# STM32N657xx register map
File version: 1.0
Registers are 32-bit, read-write, reset 0x0 unless marked. A register's access mark holds for its fields unless they carry their own. Offsets are from the block's base; [hi:lo] are bit positions; {n}, {i} and the like mark numbered series.

## RCC (part 2 of 2) — Reset and Clock Control
Base 0x46028000
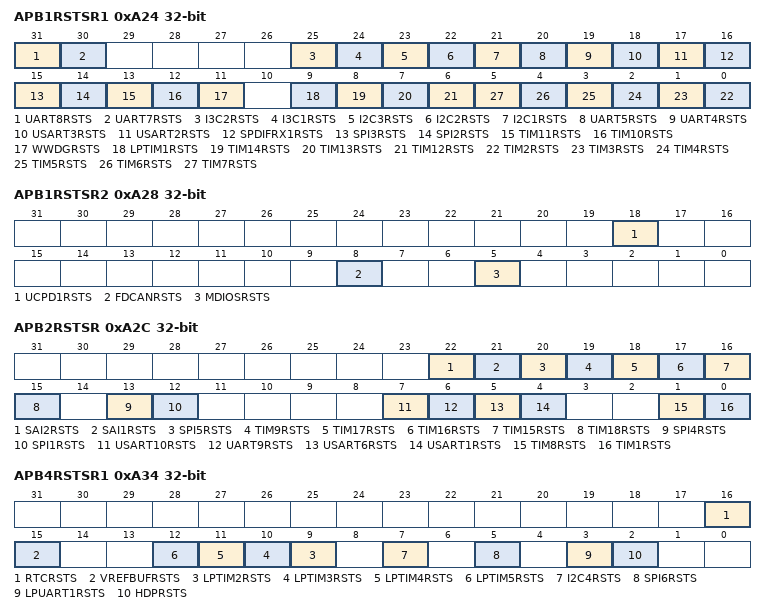
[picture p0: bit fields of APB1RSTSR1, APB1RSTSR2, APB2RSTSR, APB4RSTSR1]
0xA24 APB1RSTSR1 — RCC APB1 reset register 1
  [31] UART8RSTS — UART8 reset
  [30] UART7RSTS — UART7 reset
  [25] I3C2RSTS — I3C2 reset
  [24] I3C1RSTS — I3C1 reset
  [23] I2C3RSTS — I2C3 reset
  [22] I2C2RSTS — I2C2 reset
  [21] I2C1RSTS — I2C1 reset
  [20] UART5RSTS — UART5 reset
  [19] UART4RSTS — UART4 reset
  [18] USART3RSTS — USART3 reset
  [17] USART2RSTS — USART2 reset
  [16] SPDIFRX1RSTS — SPDIFRX1 reset
  [15] SPI3RSTS — SPI3 reset
  [14] SPI2RSTS — SPI2 reset
  [13] TIM11RSTS — TIM11 reset
  [12] TIM10RSTS — TIM10 reset
  [11] WWDGRSTS — WWDG reset
  [9] LPTIM1RSTS — LPTIM1 reset
  [8] TIM14RSTS — TIM14 reset
  [7] TIM13RSTS — TIM13 reset
  [6] TIM12RSTS — TIM12 reset
  [n-2] TIM{n}RSTS (n=2..7) — TIM{n} reset
0xA28 APB1RSTSR2 — RCC APB1 reset register 2
  [18] UCPD1RSTS — UCPD1 reset
  [8] FDCANRSTS — FDCAN reset
  [5] MDIOSRSTS — MDIOS reset
0xA2C APB2RSTSR — RCC APB2 reset register
  [22] SAI2RSTS — SAI2 reset
  [21] SAI1RSTS — SAI1 reset
  [20] SPI5RSTS — SPI5 reset
  [19] TIM9RSTS — TIM9 reset
  [18] TIM17RSTS — TIM17 reset
  [17] TIM16RSTS — TIM16 reset
  [16] TIM15RSTS — TIM15 reset
  [15] TIM18RSTS — TIM18 reset
  [13] SPI4RSTS — SPI4 reset
  [12] SPI1RSTS — SPI1 reset
  [7] USART10RSTS — USART10 reset
  [6] UART9RSTS — UART9 reset
  [5] USART6RSTS — USART6 reset
  [4] USART1RSTS — USART1 reset
  [1] TIM8RSTS — TIM8 reset
  [0] TIM1RSTS — TIM1 reset
0xA34 APB4RSTSR1 — RCC APB4 reset register 1
  [16] RTCRSTS — RTC reset
  [15] VREFBUFRSTS — VREFBUF reset
  [n+7] LPTIM{n}RSTS (n=2..5) — LPTIM{n} reset
  [7] I2C4RSTS — I2C4 reset
  [5] SPI6RSTS — SPI6 reset
  [3] LPUART1RSTS — LPUART1 reset
  [2] HDPRSTS — HDP reset
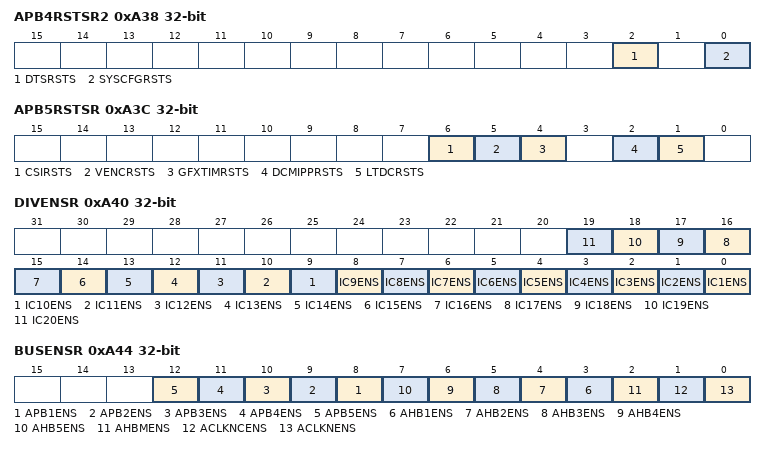
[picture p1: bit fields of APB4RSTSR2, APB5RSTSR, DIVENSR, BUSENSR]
0xA38 APB4RSTSR2 — RCC APB4 reset register 2
  [2] DTSRSTS — DTS reset
  [0] SYSCFGRSTS — SYSCFG reset
0xA3C APB5RSTSR — RCC APB5 reset register
  [6] CSIRSTS — CSI reset
  [5] VENCRSTS — VENC reset
  [4] GFXTIMRSTS — GFXTIM reset
  [2] DCMIPPRSTS — DCMIPP reset
  [1] LTDCRSTS — LTDC reset
0xA40 DIVENSR — RCC divider enable register
  [n-1] IC{n}ENS (n=1..20) — IC{n} enable
0xA44 BUSENSR — RCC bus enable register
  [n+7] APB{n}ENS (n=1..5) — APB{n} enable
  [n+2] AHB{n}ENS (n=1..5) — AHB{n} enable
  [2] AHBMENS — AHBM enable
  [1] ACLKNCENS — ACLKNC enable
  [0] ACLKNENS — ACLKN enable
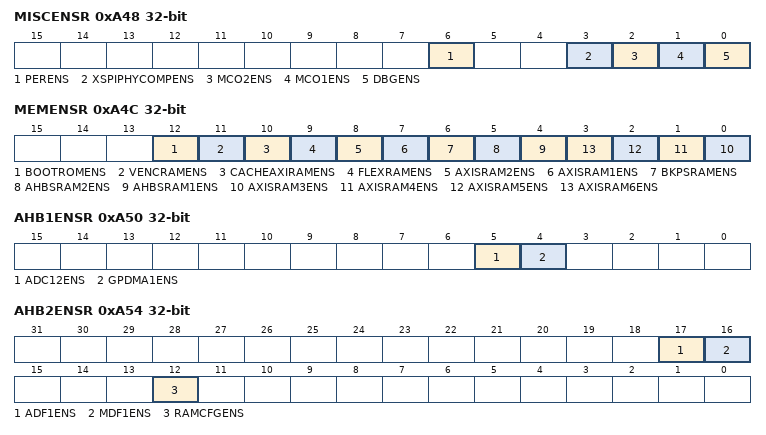
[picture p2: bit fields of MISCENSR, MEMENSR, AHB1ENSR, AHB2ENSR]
0xA48 MISCENSR — RCC miscellaneous enable register
  [6] PERENS — PER enable
  [3] XSPIPHYCOMPENS — XSPIPHYCOMP enable
  [2] MCO2ENS — MCO2 enable
  [1] MCO1ENS — MCO1 enable
  [0] DBGENS — DBG enable
0xA4C MEMENSR — RCC memory enable register
  [12] BOOTROMENS — Boot ROM enable
  [11] VENCRAMENS — VENCRAM enable
  [10] CACHEAXIRAMENS — CACHEAXIRAM enable
  [9] FLEXRAMENS — FLEXRAM enable
  [8] AXISRAM2ENS — AXISRAM2 enable
  [7] AXISRAM1ENS — AXISRAM1 enable
  [6] BKPSRAMENS — BKPSRAM enable
  [5] AHBSRAM2ENS — AHBSRAM2 enable
  [4] AHBSRAM1ENS — AHBSRAM1 enable
  [n-3] AXISRAM{n}ENS (n=3..6) — AXISRAM{n} enable
0xA50 AHB1ENSR — RCC AHB1 enable register
  [5] ADC12ENS — ADC12 enable
  [4] GPDMA1ENS — GPDMA1 enable
0xA54 AHB2ENSR — RCC AHB2 enable register
  [17] ADF1ENS — ADF1 enable
  [16] MDF1ENS — MDF1 enable
  [12] RAMCFGENS — RAMCFG enable
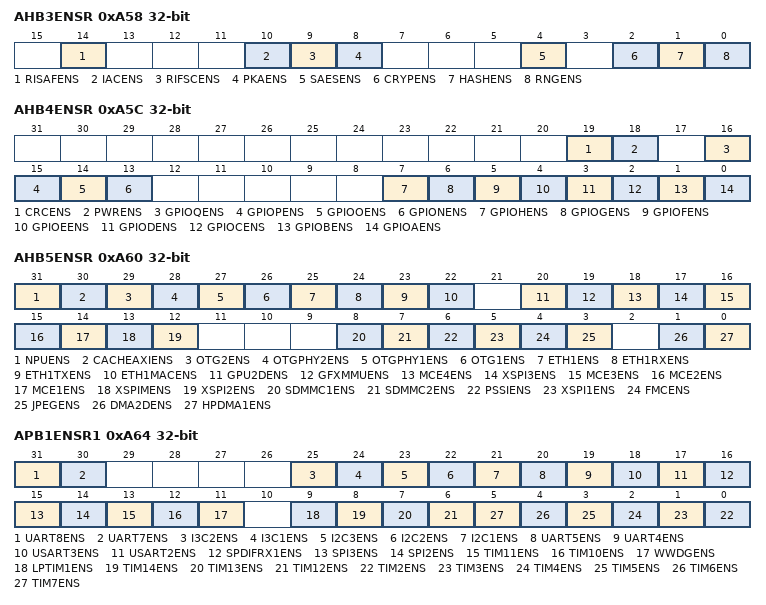
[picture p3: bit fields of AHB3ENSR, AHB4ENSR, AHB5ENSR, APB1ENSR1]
0xA58 AHB3ENSR — RCC AHB3 enable register
  [14] RISAFENS — RISAF enable
  [10] IACENS — IAC enable
  [9] RIFSCENS — RIFSC enable
  [8] PKAENS — PKA enable
  [4] SAESENS — SAES enable
  [2] CRYPENS — CRYP enable
  [1] HASHENS — HASH enable
  [0] RNGENS — RNG enable
0xA5C AHB4ENSR — RCC AHB4 enable register
  [19] CRCENS — CRC enable
  [18] PWRENS — PWR enable
  [16] GPIOQENS — GPIO Q enable
  [15] GPIOPENS — GPIO P enable
  [14] GPIOOENS — GPIO O enable
  [13] GPIONENS — GPIO N enable
  [7] GPIOHENS — GPIO H enable
  [6] GPIOGENS — GPIO G enable
  [5] GPIOFENS — GPIO F enable
  [4] GPIOEENS — GPIO E enable
  [3] GPIODENS — GPIO D enable
  [2] GPIOCENS — GPIO C enable
  [1] GPIOBENS — GPIO B enable
  [0] GPIOAENS — GPIO A enable
0xA60 AHB5ENSR — RCC AHB5 enable register
  [31] NPUENS — NPU enable
  [30] CACHEAXIENS — CACHEAXI enable
  [29] OTG2ENS — OTG2 enable
  [28] OTGPHY2ENS — OTGPHY2 enable
  [27] OTGPHY1ENS — OTGPHY1 enable
  [26] OTG1ENS — OTG1 enable
  [25] ETH1ENS — ETH1 enable
  [24] ETH1RXENS — ETH1RX enable
  [23] ETH1TXENS — ETH1TX enable
  [22] ETH1MACENS — ETH1MAC enable
  [20] GPU2DENS — GPU2D enable
  [19] GFXMMUENS — GFXMMU enable
  [18] MCE4ENS — MCE4 enable
  [17] XSPI3ENS — XSPI3 enable
  [16] MCE3ENS — MCE3 enable
  [15] MCE2ENS — MCE2 enable
  [14] MCE1ENS — MCE1 enable
  [13] XSPIMENS — XSPIM enable
  [12] XSPI2ENS — XSPI2 enable
  [8] SDMMC1ENS — SDMMC1 enable
  [7] SDMMC2ENS — SDMMC2 enable
  [6] PSSIENS — PSSI enable
  [5] XSPI1ENS — XSPI1 enable
  [4] FMCENS — FMC enable
  [3] JPEGENS — JPEG enable
  [1] DMA2DENS — DMA2D enable
  [0] HPDMA1ENS — HPDMA1 enable
0xA64 APB1ENSR1 — RCC APB1 enable register 1
  [31] UART8ENS — UART8 enable
  [30] UART7ENS — UART7 enable
  [25] I3C2ENS — I3C2 enable
  [24] I3C1ENS — I3C1 enable
  [23] I2C3ENS — I2C3 enable
  [22] I2C2ENS — I2C2 enable
  [21] I2C1ENS — I2C1 enable
  [20] UART5ENS — UART5 enable
  [19] UART4ENS — UART4 enable
  [18] USART3ENS — USART3 enable
  [17] USART2ENS — USART2 enable
  [16] SPDIFRX1ENS — SPDIFRX1 enable
  [15] SPI3ENS — SPI3 enable
  [14] SPI2ENS — SPI2 enable
  [13] TIM11ENS — TIM11 enable
  [12] TIM10ENS — TIM10 enable
  [11] WWDGENS — WWDG enable
  [9] LPTIM1ENS — LPTIM1 enable
  [8] TIM14ENS — TIM14 enable
  [7] TIM13ENS — TIM13 enable
  [6] TIM12ENS — TIM12 enable
  [n-2] TIM{n}ENS (n=2..7) — TIM{n} enable
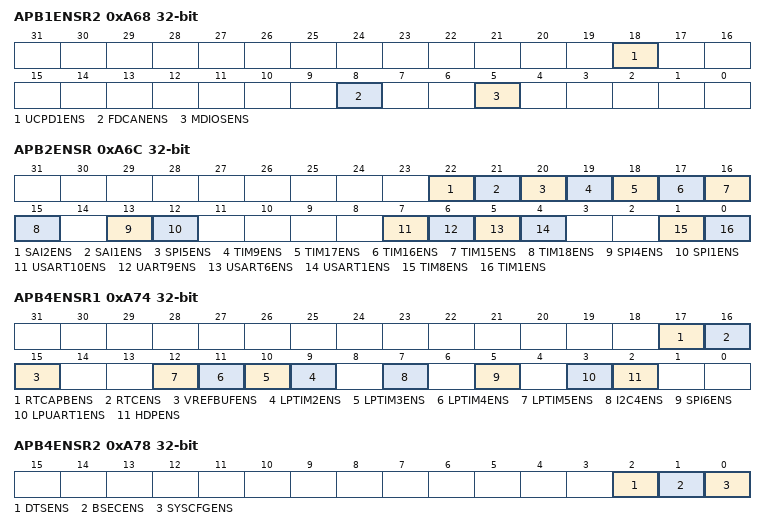
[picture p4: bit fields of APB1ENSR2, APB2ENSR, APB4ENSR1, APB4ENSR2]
0xA68 APB1ENSR2 — RCC APB1 enable register 2
  [18] UCPD1ENS — UCPD1 enable
  [8] FDCANENS — FDCAN enable
  [5] MDIOSENS — MDIOS enable
0xA6C APB2ENSR — RCC APB2 enable register
  [22] SAI2ENS — SAI2 enable
  [21] SAI1ENS — SAI1 enable
  [20] SPI5ENS — SPI5 enable
  [19] TIM9ENS — TIM9 enable
  [18] TIM17ENS — TIM17 enable
  [17] TIM16ENS — TIM16 enable
  [16] TIM15ENS — TIM15 enable
  [15] TIM18ENS — TIM18 enable
  [13] SPI4ENS — SPI4 enable
  [12] SPI1ENS — SPI1 enable
  [7] USART10ENS — USART10 enable
  [6] UART9ENS — UART9 enable
  [5] USART6ENS — USART6 enable
  [4] USART1ENS — USART1 enable
  [1] TIM8ENS — TIM8 enable
  [0] TIM1ENS — TIM1 enable
0xA70 APB3ENSR — RCC APB3 enable register
  [2] DFTENS — DFT enable
0xA74 APB4ENSR1 — RCC APB4 enable register 1
  [17] RTCAPBENS — RTCAPB enable
  [16] RTCENS — RTC enable
  [15] VREFBUFENS — VREFBUF enable
  [n+7] LPTIM{n}ENS (n=2..5) — LPTIM{n} enable
  [7] I2C4ENS — I2C4 enable
  [5] SPI6ENS — SPI6 enable
  [3] LPUART1ENS — LPUART1 enable
  [2] HDPENS — HDP enable
0xA78 APB4ENSR2 — RCC APB4 enable register 2
  [2] DTSENS — DTS enable
  [1] BSECENS — BSEC enable
  [0] SYSCFGENS — SYSCFG enable
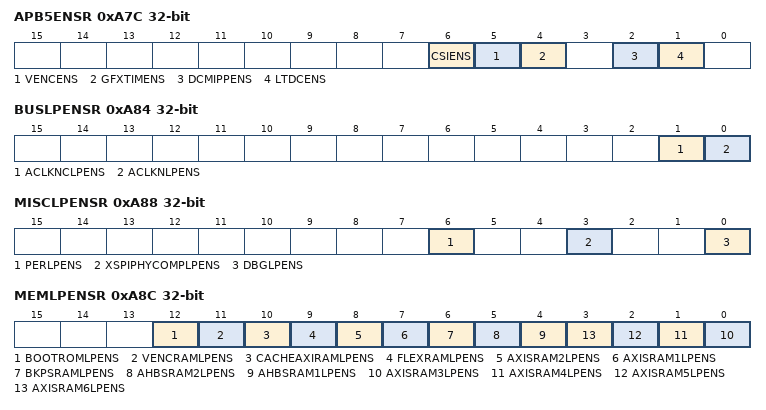
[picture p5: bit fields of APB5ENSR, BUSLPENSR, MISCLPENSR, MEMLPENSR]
0xA7C APB5ENSR — RCC APB5 enable register
  [6] CSIENS — CSI enable
  [5] VENCENS — VENC enable
  [4] GFXTIMENS — GFXTIM enable
  [2] DCMIPPENS — DCMIPP enable
  [1] LTDCENS — LTDC enable
0xA84 BUSLPENSR — RCC bus sleep enable register
  [1] ACLKNCLPENS — ACLKNC enable
  [0] ACLKNLPENS — ACLKN enable
0xA88 MISCLPENSR — RCC miscellaneous sleep enable register
  [6] PERLPENS — PER enable
  [3] XSPIPHYCOMPLPENS — XSPIPHYCOMP enable
  [0] DBGLPENS — DBG enable
0xA8C MEMLPENSR — RCC memory sleep enable register
  [12] BOOTROMLPENS — Boot ROM enable
  [11] VENCRAMLPENS — VENCRAM enable
  [10] CACHEAXIRAMLPENS — CACHEAXIRAM enable
  [9] FLEXRAMLPENS — FLEXRAM enable
  [8] AXISRAM2LPENS — AXISRAM2 enable
  [7] AXISRAM1LPENS — AXISRAM1 enable
  [6] BKPSRAMLPENS — BKPSRAM enable
  [5] AHBSRAM2LPENS — AHBSRAM2 enable
  [4] AHBSRAM1LPENS — AHBSRAM1 enable
  [n-3] AXISRAM{n}LPENS (n=3..6) — AXISRAM{n} enable
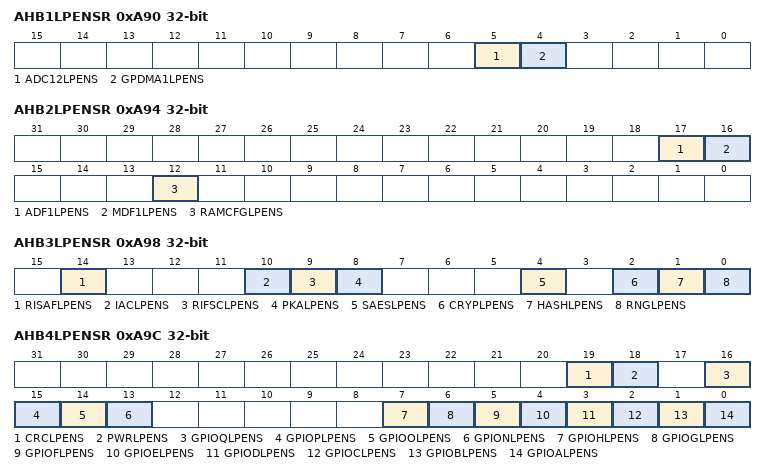
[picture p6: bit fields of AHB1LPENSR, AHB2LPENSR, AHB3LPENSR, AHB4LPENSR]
0xA90 AHB1LPENSR — RCC AHB1 sleep enable register
  [5] ADC12LPENS — ADC12 enable
  [4] GPDMA1LPENS — GPDMA1 enable
0xA94 AHB2LPENSR — RCC AHB2 sleep enable register
  [17] ADF1LPENS — ADF1 enable
  [16] MDF1LPENS — MDF1 enable
  [12] RAMCFGLPENS — RAMCFG enable
0xA98 AHB3LPENSR — RCC AHB3 sleep enable register
  [14] RISAFLPENS — RISAF enable
  [10] IACLPENS — IAC enable in Sleep mode
  [9] RIFSCLPENS — RIFSC enable
  [8] PKALPENS — PKA enable
  [4] SAESLPENS — SAES enable
  [2] CRYPLPENS — CRYP enable
  [1] HASHLPENS — HASH enable
  [0] RNGLPENS — RNG enable
0xA9C AHB4LPENSR — RCC AHB4 sleep enable register
  [19] CRCLPENS — CRC enable
  [18] PWRLPENS — PWR enable
  [16] GPIOQLPENS — GPIO Q enable
  [15] GPIOPLPENS — GPIO P enable
  [14] GPIOOLPENS — GPIO O enable
  [13] GPIONLPENS — GPIO N enable
  [7] GPIOHLPENS — GPIO H enable
  [6] GPIOGLPENS — GPIO G enable
  [5] GPIOFLPENS — GPIO F enable
  [4] GPIOELPENS — GPIO E enable
  [3] GPIODLPENS — GPIO D enable
  [2] GPIOCLPENS — GPIO C enable
  [1] GPIOBLPENS — GPIO B enable
  [0] GPIOALPENS — GPIO A enable
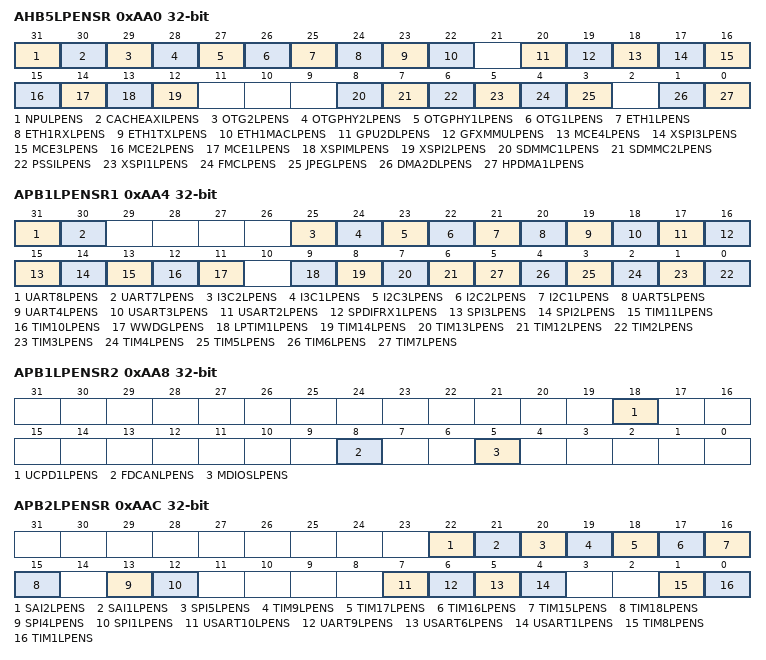
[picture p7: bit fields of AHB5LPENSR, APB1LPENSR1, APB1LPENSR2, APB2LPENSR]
0xAA0 AHB5LPENSR — RCC AHB5 sleep enable register
  [31] NPULPENS — NPU enable
  [30] CACHEAXILPENS — CACHEAXI enable
  [29] OTG2LPENS — OTG2 enable
  [28] OTGPHY2LPENS — OTGPHY2 enable
  [27] OTGPHY1LPENS — OTGPHY1 enable
  [26] OTG1LPENS — OTG1 enable
  [25] ETH1LPENS — ETH1 enable
  [24] ETH1RXLPENS — ETH1RX enable
  [23] ETH1TXLPENS — ETH1TX enable
  [22] ETH1MACLPENS — ETH1MAC enable
  [20] GPU2DLPENS — GPU2D enable
  [19] GFXMMULPENS — GFXMMU enable
  [18] MCE4LPENS — MCE4 enable
  [17] XSPI3LPENS — XSPI3 enable
  [16] MCE3LPENS — MCE3 enable
  [15] MCE2LPENS — MCE2 enable
  [14] MCE1LPENS — MCE1 enable
  [13] XSPIMLPENS — XSPIM enable
  [12] XSPI2LPENS — XSPI2 enable
  [8] SDMMC1LPENS — SDMMC1 enable
  [7] SDMMC2LPENS — SDMMC2 enable
  [6] PSSILPENS — PSSI enable
  [5] XSPI1LPENS — XSPI1 enable
  [4] FMCLPENS — FMC enable
  [3] JPEGLPENS — JPEG enable
  [1] DMA2DLPENS — DMA2D enable
  [0] HPDMA1LPENS — HPDMA1 enable
0xAA4 APB1LPENSR1 — RCC APB1 sleep enable register 1
  [31] UART8LPENS — UART8 enable
  [30] UART7LPENS — UART7 enable
  [25] I3C2LPENS — I3C2 enable
  [24] I3C1LPENS — I3C1 enable
  [23] I2C3LPENS — I2C3 enable
  [22] I2C2LPENS — I2C2 enable
  [21] I2C1LPENS — I2C1 enable
  [20] UART5LPENS — UART5 enable
  [19] UART4LPENS — UART4 enable
  [18] USART3LPENS — USART3 enable
  [17] USART2LPENS — USART2 enable
  [16] SPDIFRX1LPENS — SPDIFRX1 enable
  [15] SPI3LPENS — SPI3 enable
  [14] SPI2LPENS — SPI2 enable
  [13] TIM11LPENS — TIM11 enable
  [12] TIM10LPENS — TIM10 enable
  [11] WWDGLPENS — WWDG enable
  [9] LPTIM1LPENS — LPTIM1 enable
  [8] TIM14LPENS — TIM14 enable
  [7] TIM13LPENS — TIM13 enable
  [6] TIM12LPENS — TIM12 enable
  [n-2] TIM{n}LPENS (n=2..7) — TIM{n} enable
0xAA8 APB1LPENSR2 — RCC APB1 sleep enable register 2
  [18] UCPD1LPENS — UCPD1 enable
  [8] FDCANLPENS — FDCAN enable
  [5] MDIOSLPENS — MDIOS enable
0xAAC APB2LPENSR — RCC APB2 sleep enable register
  [22] SAI2LPENS — SAI2 enable
  [21] SAI1LPENS — SAI1 enable
  [20] SPI5LPENS — SPI5 enable
  [19] TIM9LPENS — TIM9 enable
  [18] TIM17LPENS — TIM17 enable
  [17] TIM16LPENS — TIM16 enable
  [16] TIM15LPENS — TIM15 enable
  [15] TIM18LPENS — TIM18 enable
  [13] SPI4LPENS — SPI4 enable
  [12] SPI1LPENS — SPI1 enable
  [7] USART10LPENS — USART10 enable
  [6] UART9LPENS — UART9 enable
  [5] USART6LPENS — USART6 enable
  [4] USART1LPENS — USART1 enable
  [1] TIM8LPENS — TIM8 enable
  [0] TIM1LPENS — TIM1 enable
0xAB0 APB3LPENSR — RCC APB3 sleep enable register
  [2] DFTLPENS — DFT enable
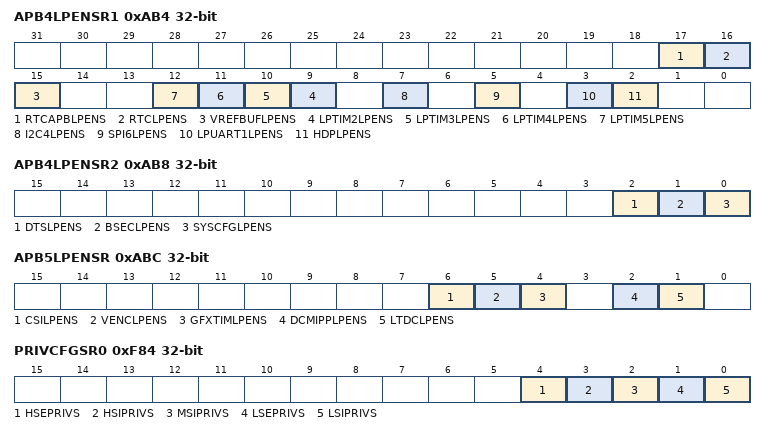
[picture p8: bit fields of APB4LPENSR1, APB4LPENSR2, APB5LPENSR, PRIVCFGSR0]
0xAB4 APB4LPENSR1 — RCC APB4 sleep enable register 1
  [17] RTCAPBLPENS — RTCAPB enable
  [16] RTCLPENS — RTC enable
  [15] VREFBUFLPENS — VREFBUF enable
  [n+7] LPTIM{n}LPENS (n=2..5) — LPTIM{n} enable
  [7] I2C4LPENS — I2C4 enable
  [5] SPI6LPENS — SPI6 enable
  [3] LPUART1LPENS — LPUART1 enable
  [2] HDPLPENS — HDP enable
0xAB8 APB4LPENSR2 — RCC APB4 sleep enable register 2
  [2] DTSLPENS — DTS enable
  [1] BSECLPENS — BSEC enable
  [0] SYSCFGLPENS — SYSCFG enable
0xABC APB5LPENSR — RCC APB5 sleep enable register
  [6] CSILPENS — CSI enable
  [5] VENCLPENS — VENC enable
  [4] GFXTIMLPENS — GFXTIM enable
  [2] DCMIPPLPENS — DCMIPP enable
  [1] LTDCLPENS — LTDC enable
0xF84 PRIVCFGSR0 — RCC oscillator privilege configuration set register 0
  [4] HSEPRIVS — Privileged protection of HSE configuration bits (enable, ready, divider)
  [3] HSIPRIVS — Privileged protection of HSI configuration bits (enable, ready, divider)
  [2] MSIPRIVS — Privileged protection of MSI configuration bits (enable, ready, divider)
  [1] LSEPRIVS — Privileged protection of LSE configuration bits (enable, ready, divider)
  [0] LSIPRIVS — Privileged protection of the LSI configuration bits (enable, ready, divider)
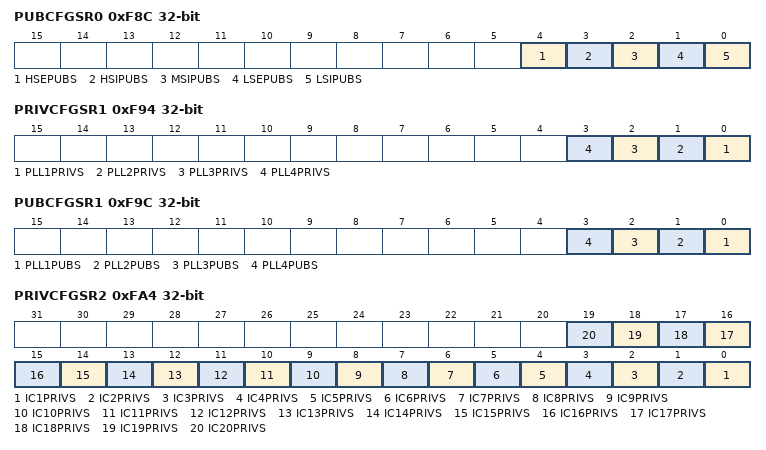
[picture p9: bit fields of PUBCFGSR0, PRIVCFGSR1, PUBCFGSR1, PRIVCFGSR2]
0xF8C PUBCFGSR0 — RCC oscillator public configuration set register 0
  [4] HSEPUBS — Public protection of he HSE configuration bits (enable, ready, divider)
  [3] HSIPUBS — Public protection of HSI configuration bits (enable, ready, divider)
  [2] MSIPUBS — Public protection of MSI configuration bits (enable, ready, divider)
  [1] LSEPUBS — Public protection of LSE configuration bits (enable, ready, divider)
  [0] LSIPUBS — Public protection of LSI configuration bits (enable, ready, divider)
0xF94 PRIVCFGSR1 — RCC PLL privilege configuration set register 1
  [n-1] PLL{n}PRIVS (n=1..4) — Privileged protection of PLL{n} configuration bits (enable, ready, divider)
0xF9C PUBCFGSR1 — RCC PLL public configuration set register 1
  [n-1] PLL{n}PUBS (n=1..4) — Public protection of PLL{n} configuration bits (enable, ready, divider)
0xFA4 PRIVCFGSR2 — RCC divider privilege configuration set register 2
  [n-1] IC{n}PRIVS (n=1..20) — Privileged protection of IC{n} configuration bits (enable, ready, divider)
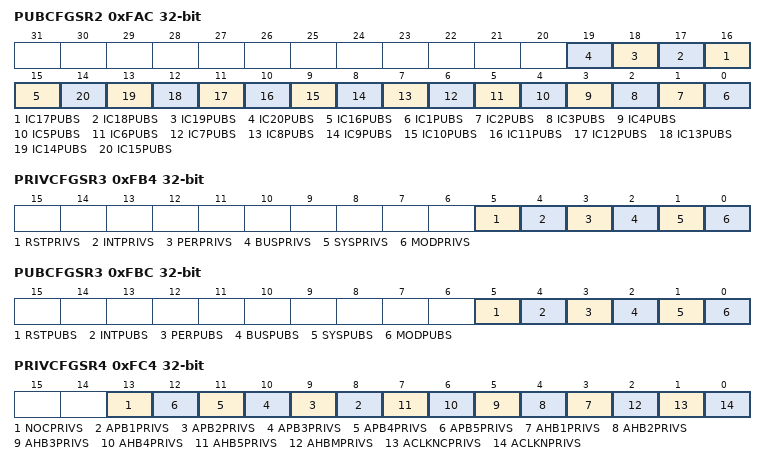
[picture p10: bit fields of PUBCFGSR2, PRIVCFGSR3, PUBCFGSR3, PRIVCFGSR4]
0xFAC PUBCFGSR2 — RCC divider public configuration set register 2
  [n-1] IC{n}PUBS (n=17..20) — Public protection of IC{n} configuration bits (enable, ready, divider)
  [15] IC16PUBS — Public protection of th IC16 configuration bits (enable, ready, divider
  [n-1] IC{n}PUBS (n=1..15) — Public protection of IC{n} configuration bits (enable, ready, divider)
0xFB4 PRIVCFGSR3 — RCC system privilege configuration set register 3
  [5] RSTPRIVS — Privileged protection of RST configuration bits (enable, ready, divider)
  [4] INTPRIVS — Privileged protection of INT configuration bits (enable, ready, divider)
  [3] PERPRIVS — Privileged protection of PER configuration bits (enable, ready, divider)
  [2] BUSPRIVS — Privileged protection of BUS configuration bits (enable, ready, divider)
  [1] SYSPRIVS — Privileged protection of SYS configuration bits (enable, ready, divider)
  [0] MODPRIVS — Privileged protection of MOD configuration bits (enable, ready, divider)
0xFBC PUBCFGSR3 — RCC system public configuration set register 3
  [5] RSTPUBS — Public protection of RST configuration bits (enable, ready, divider)
  [4] INTPUBS — Public protection of INT configuration bits (enable, ready, divider)
  [3] PERPUBS — Public protection of PER configuration bits (enable, ready, divider)
  [2] BUSPUBS — Public protection of BUS configuration bits (enable, ready, divider)
  [1] SYSPUBS — Public protection of SYS configuration bits (enable, ready, divider)
  [0] MODPUBS — Public protection of MOD configuration bits (enable, ready, divider)
0xFC4 PRIVCFGSR4 — RCC privilege configuration set register 4
  [13] NOCPRIVS — Privileged protection of NOC configuration bits (enable, ready, divider)
  [n+7] APB{n}PRIVS (n=1..5) — Privileged protection of APB{n} configuration bits (enable, ready, divider)
  [n+2] AHB{n}PRIVS (n=1..5) — Privileged protection of AHB{n} configuration bits (enable, ready, divider)
  [2] AHBMPRIVS — Privileged protection of AHBM configuration bits (enable, ready, divider)
  [1] ACLKNCPRIVS — Privileged protection of th ACLKNC configuration bits (enable, ready, divider)
  [0] ACLKNPRIVS — Privileged protection of ACLKN configuration bits (enable, ready, divider)
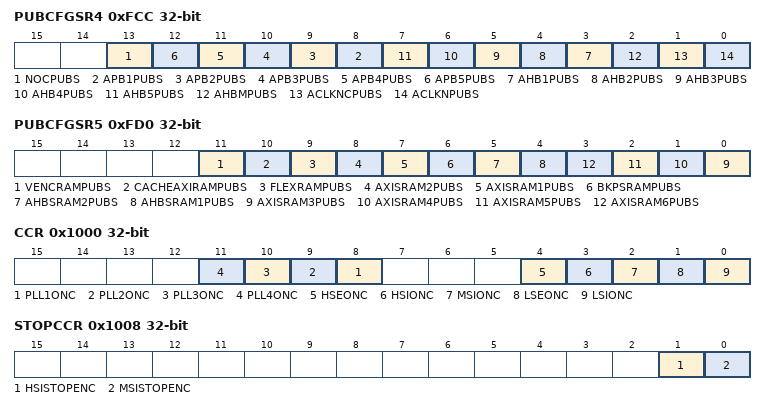
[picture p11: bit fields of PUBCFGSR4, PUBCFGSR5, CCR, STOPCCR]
0xFCC PUBCFGSR4 — RCC public configuration set register 4
  [13] NOCPUBS — Public protection of NOC configuration bits (enable, ready, divider)
  [n+7] APB{n}PUBS (n=1..5) — Public protection of APB{n} configuration bits (enable, ready, divider)
  [n+2] AHB{n}PUBS (n=1..5) — Public protection of AHB{n} configuration bits (enable, ready, divider)
  [2] AHBMPUBS — Public protection of AHBM configuration bits (enable, ready, divider)
  [1] ACLKNCPUBS — Public protection of ACLKNC configuration bits (enable, ready, divider)
  [0] ACLKNPUBS — Public protection of ACLKN configuration bits (enable, ready, divider)
0xFD0 PUBCFGSR5 — RCC public configuration set register 5
  [11] VENCRAMPUBS — Public protection of VENCRAM configuration bits (enable, ready, divider)
  [10] CACHEAXIRAMPUBS — Public protection of CACHEAXIRAM configuration bits (enable, ready, divider)
  [9] FLEXRAMPUBS — Public protection of FLEXRAM configuration bits (enable, ready, divider)
  [8] AXISRAM2PUBS — Public protection of AXISRAM2 configuration bits (enable, ready, divider)
  [7] AXISRAM1PUBS — Public protection of AXISRAM1 configuration bits (enable, ready, divider)
  [6] BKPSRAMPUBS — Public protection of BKPSRAM configuration bits (enable, ready, divider)
  [5] AHBSRAM2PUBS — Public protection of AHBSRAM2 configuration bits (enable, ready, divider)
  [4] AHBSRAM1PUBS — Public protection of AHBSRAM1 configuration bits (enable, ready, divider)
  [n-3] AXISRAM{n}PUBS (n=3..6) — Public protection of AXISRAM{n} configuration bits (enable, ready, divider)
0x1000 CCR — RCC control clear register
  [n+7] PLL{n}ONC (n=1..4) — PLL{n} oscillator enable
  [4] HSEONC — HSE oscillator enable
  [3] HSIONC — HSI oscillator enable
  [2] MSIONC — MSI oscillator enable
  [1] LSEONC — LSE oscillator enable
  [0] LSIONC — LSI oscillator enable
0x1008 STOPCCR — RCC Stop mode configuration clear register
  [1] HSISTOPENC — HSI oscillator enable
  [0] MSISTOPENC — MSI oscillator enable
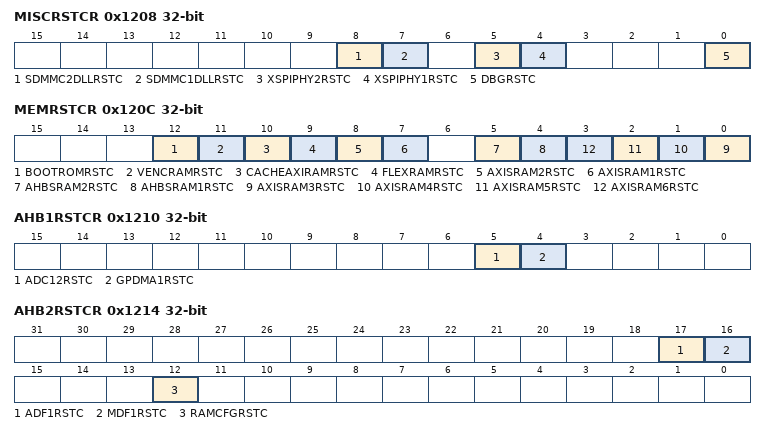
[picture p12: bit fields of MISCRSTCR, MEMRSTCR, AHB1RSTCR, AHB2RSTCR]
0x1208 MISCRSTCR — RCC miscellaneous reset clear register
  [8] SDMMC2DLLRSTC — SDMMC2DLL reset
  [7] SDMMC1DLLRSTC — SDMMC1DLL reset
  [5] XSPIPHY2RSTC — XSPIPHY2 reset
  [4] XSPIPHY1RSTC — XSPIPHY1 reset
  [0] DBGRSTC — DBG reset
0x120C MEMRSTCR — RCC memory reset clear register
  [12] BOOTROMRSTC — Boot ROM reset
  [11] VENCRAMRSTC — VENCRAM reset
  [10] CACHEAXIRAMRSTC — CACHEAXIRAM reset
  [9] FLEXRAMRSTC — FLEXRAM reset
  [8] AXISRAM2RSTC — AXISRAM2 reset
  [7] AXISRAM1RSTC — AXISRAM1 reset
  [5] AHBSRAM2RSTC — AHBSRAM2 reset
  [4] AHBSRAM1RSTC — AHBSRAM1 reset
  [n-3] AXISRAM{n}RSTC (n=3..6) — AXISRAM{n} reset
0x1210 AHB1RSTCR — RCC AHB1 reset clear register
  [5] ADC12RSTC — ADC12 reset
  [4] GPDMA1RSTC — GPDMA1 reset
0x1214 AHB2RSTCR — RCC AHB2 reset clear register
  [17] ADF1RSTC — ADF1 reset
  [16] MDF1RSTC — MDF1 reset
  [12] RAMCFGRSTC — RAMCFG reset
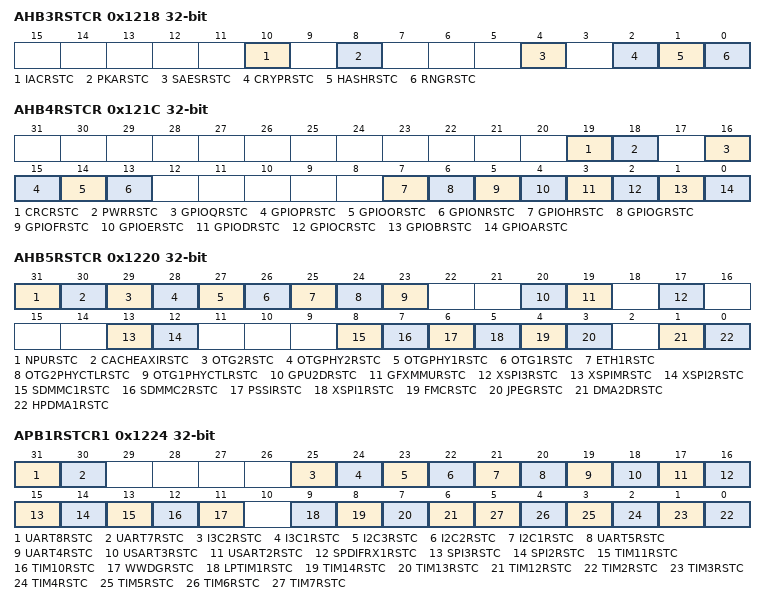
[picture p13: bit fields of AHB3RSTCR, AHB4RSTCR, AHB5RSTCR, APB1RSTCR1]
0x1218 AHB3RSTCR — RCC AHB3 reset r clear register
  [10] IACRSTC — IAC reset
  [8] PKARSTC — PKA reset
  [4] SAESRSTC — SAES reset
  [2] CRYPRSTC — CRYP reset
  [1] HASHRSTC — HASH reset
  [0] RNGRSTC — RNG reset
0x121C AHB4RSTCR — RCC AHB4 reset clear register
  [19] CRCRSTC — CRC reset
  [18] PWRRSTC — PWR reset
  [16] GPIOQRSTC — GPIO Q reset
  [15] GPIOPRSTC — GPIO P reset
  [14] GPIOORSTC — GPIO O reset
  [13] GPIONRSTC — GPIO N reset
  [7] GPIOHRSTC — GPIO H reset
  [6] GPIOGRSTC — GPIO G reset
  [5] GPIOFRSTC — GPIO F reset
  [4] GPIOERSTC — GPIO E reset
  [3] GPIODRSTC — GPIO D reset
  [2] GPIOCRSTC — GPIO C reset
  [1] GPIOBRSTC — GPIO B reset
  [0] GPIOARSTC — GPIO A reset
0x1220 AHB5RSTCR — RCC AHB5 reset clear register
  [31] NPURSTC — NPU reset
  [30] CACHEAXIRSTC — CACHEAXI reset
  [29] OTG2RSTC — OTG2 reset
  [28] OTGPHY2RSTC — OTGPHY2 reset
  [27] OTGPHY1RSTC — OTGPHY1 reset
  [26] OTG1RSTC — OTG1 reset
  [25] ETH1RSTC — ETH1 reset
  [24] OTG2PHYCTLRSTC — OTG2PHYCTL reset
  [23] OTG1PHYCTLRSTC — OTG1PHYCTL reset
  [20] GPU2DRSTC — GPU2D reset
  [19] GFXMMURSTC — GFXMMU reset
  [17] XSPI3RSTC — XSPI3 reset
  [13] XSPIMRSTC — XSPIM reset
  [12] XSPI2RSTC — XSPI2 reset
  [8] SDMMC1RSTC — SDMMC1 reset
  [7] SDMMC2RSTC — SDMMC2 reset
  [6] PSSIRSTC — PSSI reset
  [5] XSPI1RSTC — XSPI1 reset
  [4] FMCRSTC — FMC reset
  [3] JPEGRSTC — JPEG reset
  [1] DMA2DRSTC — DMA2D reset
  [0] HPDMA1RSTC — HPDMA1 reset
0x1224 APB1RSTCR1 — RCC APB1 reset clear register 1
  [31] UART8RSTC — UART8 reset
  [30] UART7RSTC — UART7 reset
  [25] I3C2RSTC — I3C2 reset
  [24] I3C1RSTC — I3C1 reset
  [23] I2C3RSTC — I2C3 reset
  [22] I2C2RSTC — I2C2 reset
  [21] I2C1RSTC — I2C1 reset
  [20] UART5RSTC — UART5 reset
  [19] UART4RSTC — UART4 reset
  [18] USART3RSTC — USART3 reset
  [17] USART2RSTC — USART2 reset
  [16] SPDIFRX1RSTC — SPDIFRX1 reset
  [15] SPI3RSTC — SPI3 reset
  [14] SPI2RSTC — SPI2 reset
  [13] TIM11RSTC — TIM11 reset
  [12] TIM10RSTC — TIM10 reset
  [11] WWDGRSTC — WWDG reset
  [9] LPTIM1RSTC — LPTIM1 reset
  [8] TIM14RSTC — TIM14 reset
  [7] TIM13RSTC — TIM13 reset
  [6] TIM12RSTC — TIM12 reset
  [n-2] TIM{n}RSTC (n=2..7) — TIM{n} reset
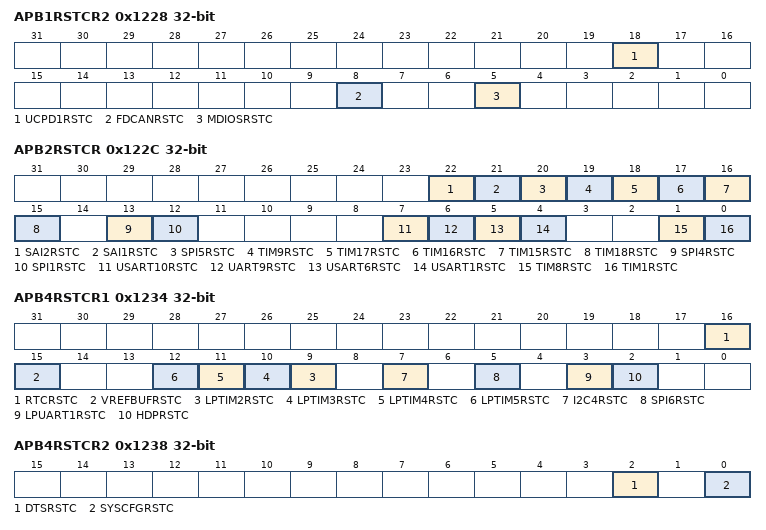
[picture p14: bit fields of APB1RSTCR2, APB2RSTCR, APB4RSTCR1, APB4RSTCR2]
0x1228 APB1RSTCR2 — RCC APB1 reset clear register 2
  [18] UCPD1RSTC — UCPD1 reset
  [8] FDCANRSTC — FDCAN reset
  [5] MDIOSRSTC — MDIOS reset
0x122C APB2RSTCR — RCC APB2 reset clear register
  [22] SAI2RSTC — SAI2 reset
  [21] SAI1RSTC — SAI1 reset
  [20] SPI5RSTC — SPI5 reset
  [19] TIM9RSTC — TIM9 reset
  [18] TIM17RSTC — TIM17 reset
  [17] TIM16RSTC — TIM16 reset
  [16] TIM15RSTC — TIM15 reset
  [15] TIM18RSTC — TIM18 reset
  [13] SPI4RSTC — SPI4 reset
  [12] SPI1RSTC — SPI1 reset
  [7] USART10RSTC — USART10 reset
  [6] UART9RSTC — UART9 reset
  [5] USART6RSTC — USART6 reset
  [4] USART1RSTC — USART1 reset
  [1] TIM8RSTC — TIM8 reset
  [0] TIM1RSTC — TIM1 reset
0x1234 APB4RSTCR1 — RCC APB4 reset clear register 1
  [16] RTCRSTC — RTC reset
  [15] VREFBUFRSTC — VREFBUF reset
  [n+7] LPTIM{n}RSTC (n=2..5) — LPTIM{n} reset
  [7] I2C4RSTC — I2C4 reset
  [5] SPI6RSTC — SPI6 reset
  [3] LPUART1RSTC — LPUART1 reset
  [2] HDPRSTC — HDP reset
0x1238 APB4RSTCR2 — RCC APB4 reset clear register 2
  [2] DTSRSTC — DTS reset
  [0] SYSCFGRSTC — SYSCFG reset
0x123C APB5RSTCR — RCC APB5 reset clear register
  [6] CSIRSTC — CSI reset
  [5] VENCRSTC — VENC reset
  [4] GFXTIMRSTC — GFXTIM reset
  [2] DCMIPPRSTC — DCMIPP reset
  [1] LTDCRSTC — LTDC reset
0x1240 DIVENCR — RCC divider enable clear register
  [n-1] IC{n}ENC (n=1..20) — IC{n} enable
0x1244 BUSENCR — RCC bus enable clear register
  [n+7] APB{n}ENC (n=1..5) — APB{n} enable
  [n+2] AHB{n}ENC (n=1..5) — AHB{n} enable
  [2] AHBMENC — AHBM enable
  [1] ACLKNCENC — ACLKNC enable
  [0] ACLKNENC — ACLKN enable
0x1248 MISCENCR — RCC miscellaneous enable clear register
  [6] PERENC — PER enable
  [3] XSPIPHYCOMPENC — XSPIPHYCOMP enable
  [2] MCO2ENC — MCO2 enable
  [1] MCO1ENC — MCO1 enable
  [0] DBGENC — DBG enable
0x124C MEMENCR — RCC memory enable clear register
  [12] BOOTROMENC — Boot ROM enable
  [11] VENCRAMENC — VENCRAM enable
  [10] CACHEAXIRAMENC — CACHEAXIRAM enable
  [9] FLEXRAMENC — FLEXRAM enable
  [8] AXISRAM2ENC — AXISRAM2 enable
  [7] AXISRAM1ENC — AXISRAM1 enable
  [6] BKPSRAMENC — BKPSRAM enable
  [5] AHBSRAM2ENC — AHBSRAM2 enable
  [4] AHBSRAM1ENC — AHBSRAM1 enable
  [n-3] AXISRAM{n}ENC (n=3..6) — AXISRAM{n} enable
0x1250 AHB1ENCR — RCC AHB1 enable clear register
  [5] ADC12ENC — ADC12 enable
  [4] GPDMA1ENC — GPDMA1 enable
0x1254 AHB2ENCR — RCC AHB2 enable clear register
  [17] ADF1ENC — ADF1 enable
  [16] MDF1ENC — MDF1 enable
  [12] RAMCFGENC — RAMCFG enable
0x1258 AHB3ENCR — RCC AHB3 enable clear register
  [14] RISAFENC — RISAF enable
  [10] IACENC — IAC enable
  [9] RIFSCENC — RIFSC enable
  [8] PKAENC — PKA enable
  [4] SAESENC — SAES enable
  [2] CRYPENC — CRYP enable
  [1] HASHENC — HASH enable
  [0] RNGENC — RNG enable
0x125C AHB4ENCR — RCC AHB4 enable clear register
  [19] CRCENC — CRC enable
  [18] PWRENC — PWR enable
  [16] GPIOQENC — GPIO Q enable
  [15] GPIOPENC — GPIO P enable
  [14] GPIOOENC — GPIO O enable
  [13] GPIONENC — GPIO N enable
  [7] GPIOHENC — GPIO H enable
  [6] GPIOGENC — GPIO G enable
  [5] GPIOFENC — GPIO F enable
  [4] GPIOEENC — GPIO E enable
  [3] GPIODENC — GPIO D enable
  [2] GPIOCENC — GPIO C enable
  [1] GPIOBENC — GPIO B enable
  [0] GPIOAENC — GPIO A enable
0x1260 AHB5ENCR — RCC AHB5 enable clear register
  [31] NPUENC — NPU enable
  [30] CACHEAXIENC — CACHEAXI enable
  [29] OTG2ENC — OTG2 enable
  [28] OTGPHY2ENC — OTGPHY2 enable
  [27] OTGPHY1ENC — OTGPHY1 enable
  [26] OTG1ENC — OTG1 enable
  [25] ETH1ENC — ETH1 enable
  [24] ETH1RXENC — ETH1RX enable
  [23] ETH1TXENC — ETH1TX enable
  [22] ETH1MACENC — ETH1MAC enable
  [20] GPU2DENC — GPU2D enable
  [19] GFXMMUENC — GFXMMU enable
  [18] MCE4ENC — MCE4 enable
  [17] XSPI3ENC — XSPI3 enable
  [16] MCE3ENC — MCE3 enable
  [15] MCE2ENC — MCE2 enable
  [14] MCE1ENC — MCE1 enable
  [13] XSPIMENC — XSPIM enable
  [12] XSPI2ENC — XSPI2 enable
  [8] SDMMC1ENC — SDMMC1 enable
  [7] SDMMC2ENC — SDMMC2 enable
  [6] PSSIENC — PSSI enable
  [5] XSPI1ENC — XSPI1 enable
  [4] FMCENC — FMC enable
  [3] JPEGENC — JPEG enable
  [1] DMA2DENC — DMA2D enable
  [0] HPDMA1ENC — HPDMA1 enable
0x1264 APB1ENCR1 — RCC APB1 enable clear register 1
  [31] UART8ENC — UART8 enable
  [30] UART7ENC — UART7 enable
  [25] I3C2ENC — I3C2 enable
  [24] I3C1ENC — I3C1 enable
  [23] I2C3ENC — I2C3 enable
  [22] I2C2ENC — I2C2 enable
  [21] I2C1ENC — I2C1 enable
  [20] UART5ENC — UART5 enable
  [19] UART4ENC — UART4 enable
  [18] USART3ENC — USART3 enable
  [17] USART2ENC — USART2 enable
  [16] SPDIFRX1ENC — SPDIFRX1 enable
  [15] SPI3ENC — SPI3 enable
  [14] SPI2ENC — SPI2 enable
  [13] TIM11ENC — TIM11 enable
  [12] TIM10ENC — TIM10 enable
  [9] LPTIM1ENC — LPTIM1 enable
  [8] TIM14ENC — TIM14 enable
  [7] TIM13ENC — TIM13 enable
  [6] TIM12ENC — TIM12 enable
  [n-2] TIM{n}ENC (n=2..7) — TIM{n} enable
0x1268 APB1ENCR2 — RCC APB1 enable clear register 2
  [18] UCPD1ENC — UCPD1 enable
  [8] FDCANENC — FDCAN enable
  [5] MDIOSENC — MDIOS enable
0x126C APB2ENCR — RCC APB2 enable clear register
  [22] SAI2ENC — SAI2 enable
  [21] SAI1ENC — SAI1 enable
  [20] SPI5ENC — SPI5 enable
  [19] TIM9ENC — TIM9 enable
  [18] TIM17ENC — TIM17 enable
  [17] TIM16ENC — TIM16 enable
  [16] TIM15ENC — TIM15 enable
  [15] TIM18ENC — TIM18 enable
  [13] SPI4ENC — SPI4 enable
  [12] SPI1ENC — SPI1 enable
  [7] USART10ENC — USART10 enable
  [6] UART9ENC — UART9 enable
  [5] USART6ENC — USART6 enable
  [4] USART1ENC — USART1 enable
  [1] TIM8ENC — TIM8 enable
  [0] TIM1ENC — TIM1 enable
0x1270 APB3ENCR — RCC APB3 enable clear register
  [2] DFTENC — DFT enable
0x1274 APB4ENCR1 — RCC APB4 enable clear register 1
  [17] RTCAPBENC — RTCAPB enable
  [16] RTCENC — RTC enable
  [15] VREFBUFENC — VREFBUF enable
  [n+7] LPTIM{n}ENC (n=2..5) — LPTIM{n} enable
  [7] I2C4ENC — I2C4 enable
  [5] SPI6ENC — SPI6 enable
  [3] LPUART1ENC — LPUART1 enable
  [2] HDPENC — HDP enable
0x1278 APB4ENCR2 — RCC APB4 enable clear register 2
  [2] DTSENC — DTS enable
  [1] BSECENC — BSEC enable
  [0] SYSCFGENC — SYSCFG enable
0x127C APB5ENCR — RCC APB5 enable clear register
  [6] CSIENC — CSI enable
  [5] VENCENC — VENC enable
  [4] GFXTIMENC — GFXTIM enable
  [2] DCMIPPENC — DCMIPP enable
  [1] LTDCENC — LTDC enable
0x1284 BUSLPENCR — RCC bus sleep enable clear register
  [1] ACLKNCLPENC — ACLKNC enable in Sleep mode
  [0] ACLKNLPENC — ACLKN enable in Sleep mode
0x1288 MISCLPENCR — RCC miscellaneous sleep enable clear register
  [6] PERLPENC — PER enable in Sleep mode
  [3] XSPIPHYCOMPLPENC — XSPIPHYCOMP enable in Sleep mode
  [0] DBGLPENC — DBG enable in Sleep mode
0x128C MEMLPENCR — RCC memory sleep enable clear register
  [12] BOOTROMLPENC — Boot ROM enable in Sleep mode
  [11] VENCRAMLPENC — VENCRAM enable in Sleep mode
  [10] CACHEAXIRAMLPENC — CACHEAXIRAM enable in Sleep mode
  [9] FLEXRAMLPENC — FLEXRAM enable in Sleep mode
  [8] AXISRAM2LPENC — AXISRAM2 enable in Sleep mode
  [7] AXISRAM1LPENC — AXISRAM1 enable in Sleep mode
  [6] BKPSRAMLPENC — BKPSRAM enable in Sleep mode
  [5] AHBSRAM2LPENC — AHBSRAM2 enable in Sleep mode
  [4] AHBSRAM1LPENC — AHBSRAM1 enable in Sleep mode
  [n-3] AXISRAM{n}LPENC (n=3..6) — AXISRAM{n} enable in Sleep mode
0x1290 AHB1LPENCR — RCC AHB1 sleep enable clear register
  [5] ADC12LPENC — ADC12 enable in Sleep mode
  [4] GPDMA1LPENC — GPDMA1 enable in Sleep mode
0x1294 AHB2LPENCR — RCC AHB2 sleep enable clear register
  [17] ADF1LPENC — ADF1 enable in Sleep mode
  [16] MDF1LPENC — MDF1 enable in Sleep mode
  [12] RAMCFGLPENC — RAMCFG enable in Sleep mode
0x1298 AHB3LPENCR — RCC AHB3 sleep enable clear register
  [14] RISAFLPENC — RISAF enable in Sleep mode
  [10] IACLPENC — IAC enable in Sleep mode
  [9] RIFSCLPENC — RIFSC enable in Sleep mode
  [8] PKALPENC — PKA enable in Sleep mode
  [4] SAESLPENC — SAES enable in Sleep mode
  [2] CRYPLPENC — CRYP enable in Sleep mode
  [1] HASHLPENC — HASH enable in Sleep mode
  [0] RNGLPENC — RNG enable in Sleep mode
0x129C AHB4LPENCR — RCC AHB4 sleep enable clear register
  [19] CRCLPENC — CRC enable in Sleep mode
  [18] PWRLPENC — PWR enable in Sleep mode
  [16] GPIOQLPENC — GPIO Q enable in Sleep mode
  [15] GPIOPLPENC — GPIO P enable in Sleep mode
  [14] GPIOOLPENC — GPIO O enable in Sleep mode
  [13] GPIONLPENC — GPIO N enable in Sleep mode
  [7] GPIOHLPENC — GPIO H enable in Sleep mode
  [6] GPIOGLPENC — GPIO G enable in Sleep mode
  [5] GPIOFLPENC — GPIO F enable in Sleep mode
  [4] GPIOELPENC — GPIO E enable in Sleep mode
  [3] GPIODLPENC — GPIO D enable in Sleep mode
  [2] GPIOCLPENC — GPIO C enable in Sleep mode
  [1] GPIOBLPENC — GPIO B enable in Sleep mode
  [0] GPIOALPENC — GPIO A enable in Sleep mode
0x12A0 AHB5LPENCR — RCC AHB5 sleep enable clear register
  [31] NPULPENC — NPU enable in Sleep mode
  [30] CACHEAXILPENC — CACHEAXI enable in Sleep mode
  [29] OTG2LPENC — OTG2 enable in Sleep mode
  [28] OTGPHY2LPENC — OTGPHY2 enable in Sleep mode
  [27] OTGPHY1LPENC — OTGPHY1 enable in Sleep mode
  [26] OTG1LPENC — OTG1 enable in Sleep mode
  [25] ETH1LPENC — ETH1 enable in Sleep mode
  [24] ETH1RXLPENC — ETH1RX enable in Sleep mode
  [23] ETH1TXLPENC — ETH1TX enable in Sleep mode
  [22] ETH1MACLPENC — ETH1MAC enable in Sleep mode
  [20] GPU2DLPENC — GPU2D enable in Sleep mode
  [19] GFXMMULPENC — GFXMMU enable in Sleep mode
  [18] MCE4LPENC — MCE4 enable in Sleep mode
  [17] XSPI3LPENC — XSPI3 enable in Sleep mode
  [16] MCE3LPENC — MCE3 enable in Sleep mode
  [15] MCE2LPENC — MCE2 enable in Sleep mode
  [14] MCE1LPENC — MCE1 enable in Sleep mode
  [13] XSPIMLPENC — XSPIM enable in Sleep mode
  [12] XSPI2LPENC — XSPI2 enable in Sleep mode
  [8] SDMMC1LPENC — SDMMC1 enable in Sleep mode
  [7] SDMMC2LPENC — SDMMC2 enable in Sleep mode
  [6] PSSILPENC — PSSI enable in Sleep mode
  [5] XSPI1LPENC — XSPI1 enable in Sleep mode
  [4] FMCLPENC — FMC enable in Sleep mode
  [3] JPEGLPENC — JPEG enable in Sleep mode
  [1] DMA2DLPENC — DMA2D enable in Sleep mode
  [0] HPDMA1LPENC — HPDMA1 enable in Sleep mode
0x12A4 APB1LPENCR1 — RCC APB1 sleep enable clear register 1
  [31] UART8LPENC — UART8 enable
  [30] UART7LPENC — UART7 enable
  [25] I3C2LPENC — I3C2 enable
  [24] I3C1LPENC — I3C1 enable
  [23] I2C3LPENC — I2C3 enable
  [22] I2C2LPENC — I2C2 enable
  [21] I2C1LPENC — I2C1 enable
  [20] UART5LPENC — UART5 enable
  [19] UART4LPENC — UART4 enable
  [18] USART3LPENC — USART3 enable
  [17] USART2LPENC — USART2 enable
  [16] SPDIFRX1LPENC — SPDIFRX1 enable
  [15] SPI3LPENC — SPI3 enable
  [14] SPI2LPENC — SPI2 enable
  [13] TIM11LPENC — TIM11 enable
  [12] TIM10LPENC — TIM10 enable
  [11] WWDGLPENC — WWDG enable
  [9] LPTIM1LPENC — LPTIM1 enable
  [8] TIM14LPENC — TIM14 enable
  [7] TIM13LPENC — TIM13 enable
  [6] TIM12LPENC — TIM12 enable
  [n-2] TIM{n}LPENC (n=2..7) — TIM{n} enable
0x12A8 APB1LPENCR2 — RCC APB1 sleep enable clear register 2
  [18] UCPD1LPENC — UCPD1 enable
  [8] FDCANLPENC — FDCAN enable
  [5] MDIOSLPENC — MDIOS enable
0x12AC APB2LPENCR — RCC APB2 sleep enable clear register
  [22] SAI2LPENC — SAI2 enable
  [21] SAI1LPENC — SAI1 enable
  [20] SPI5LPENC — SPI5 enable
  [19] TIM9LPENC — TIM9 enable
  [18] TIM17LPENC — TIM17 enable
  [17] TIM16LPENC — TIM16 enable
  [16] TIM15LPENC — TIM15 enable
  [15] TIM18LPENC — TIM18 enable
  [13] SPI4LPENC — SPI4 enable
  [12] SPI1LPENC — SPI1 enable
  [7] USART10LPENC — USART10 enable
  [6] UART9LPENC — UART9 enable
  [5] USART6LPENC — USART6 enable
  [4] USART1LPENC — USART1 enable
  [1] TIM8LPENC — TIM8 enable
  [0] TIM1LPENC — TIM1 enable
0x12B0 APB3LPENCR — RCC APB3 sleep enable clear register
  [2] DFTLPENC — DFT enable
0x12B4 APB4LPENCR1 — RCC APB4 sleep enable clear register 1
  [17] RTCAPBLPENC — RTCAPB enable
  [16] RTCLPENC — RTC enable
  [15] VREFBUFLPENC — VREFBUF enable
  [n+7] LPTIM{n}LPENC (n=2..5) — LPTIM{n} enable
  [7] I2C4LPENC — I2C4 enable
  [5] SPI6LPENC — SPI6 enable
  [3] LPUART1LPENC — LPUART1 enable
  [2] HDPLPENC — HDP enable
0x12B8 APB4LPENCR2 — RCC APB4 sleep enable clear register 2
  [2] DTSLPENC — DTS enable
  [1] BSECLPENC — BSEC enable
  [0] SYSCFGLPENC — SYSCFG enable
0x12BC APB5LPENCR — RCC APB5 sleep enable clear register
  [6] CSILPENC — CSI sleep enable
  [5] VENCLPENC — VENC sleep enable
  [4] GFXTIMLPENC — GFXTIM sleep enable
  [2] DCMIPPLPENC — DCMIPP sleep enable
  [1] LTDCLPENC — LTDC sleep enable
0x1784 PRIVCFGCR0 — RCC oscillator privilege configuration clear register 0
  [4] HSEPRIVC — Privileged protection of HSE configuration bits (enable, ready, divider)
  [3] HSIPRIVC — Privileged protection of HSI configuration bits (enable, ready, divider)
  [2] MSIPRIVC — Privileged protection of MSI configuration bits (enable, ready, divider)
  [1] LSEPRIVC — Privileged protection of LSE configuration bits (enable, ready, divider)
  [0] LSIPRIVC — Privileged protection of LSI configuration bits (enable, ready, divider)
0x178C PUBCFGCR0 — RCC oscillator public configuration clear register 0
  [4] HSEPUBC — Public protection of HSE configuration bits (enable, ready, divider)
  [3] HSIPUBC — Public protection of HSI configuration bits (enable, ready, divider)
  [2] MSIPUBC — Public protection of MSI configuration bits (enable, ready, divider)
  [1] LSEPUBC — Public protection of LSE configuration bits (enable, ready, divider)
  [0] LSIPUBC — Public protection of LSI configuration bits (enable, ready, divider)
0x1794 PRIVCFGCR1 — RCC PLL privilege configuration clear register 1
  [n-1] PLL{n}PRIVC (n=1..4) — Privileged protection of PLL{n} configuration bits (enable, ready, divider)
0x179C PUBCFGCR1 — RCC PLL public configuration clear register 1
  [3] PLL4PUBC — Public protection of PLL4 configuration bits (enable, ready, divider)
  [2] PLL3PUBC — Public protection of PLL3 configuration bits (enable, ready, divider)
  [1] PLL2PUBC — Public protection of te PLL2 configuration bits (enable, ready, divider)
  [0] PLL1PUBC — Public protection of th PLL1 configuration bits (enable, ready, divider)
0x17A4 PRIVCFGCR2 — RCC divider privilege configuration clear register 2
  [n-1] IC{n}PRIVC (n=6..20) — Privileged protection of IC{n} configuration bits (enable, ready, divider)
  [n-1] IC{n}PRIVC (n=1..5) — Privileged protection of the IC{n} configuration bits (enable, ready, divider)
0x17AC PUBCFGCR2 — RCC divider public configuration clear register 2
  [n-1] IC{n}PUBC (n=1..20) — Public protection of IC{n} configuration bits (enable, ready, divider)
0x17B4 PRIVCFGCR3 — RCC system privilege configuration clear register 3
  [5] RSTPRIVC — Privileged protection of RST configuration bits (enable, ready, divider)
  [4] INTPRIVC — Privileged protection of INT configuration bits (enable, ready, divider)
  [3] PERPRIVC — Privileged protection of PER configuration bits (enable, ready, divider)
  [2] BUSPRIVC — Privileged protection of BUS configuration bits (enable, ready, divider)
  [1] SYSPRIVC — Privileged protection of SYS configuration bits (enable, ready, divider)
  [0] MODPRIVC — Privileged protection of MOD configuration bits (enable, ready, divider)
0x17BC PUBCFGCR3 — RCC system public configuration clear register 3
  [5] RSTPUBC — Public protection of RST configuration bits (enable, ready, divider)
  [4] INTPUBC — Public protection of INT configuration bits (enable, ready, divider)
  [3] PERPUBC — Public protection of PER configuration bits (enable, ready, divider)
  [2] BUSPUBC — Public protection of BUS configuration bits (enable, ready, divider)
  [1] SYSPUBC — Public protection of SYS configuration bits (enable, ready, divider)
  [0] MODPUBC — Public protection of MOD configuration bits (enable, ready, divider)
0x17C4 PRIVCFGCR4 — RCC privilege configuration clear register 4
  [13] NOCPRIVC — Privileged protection of NOC configuration bits (enable, ready, divider)
  [n+7] APB{n}PRIVC (n=1..5) — Privileged protection of APB{n} configuration bits (enable, ready, divider)
  [n+2] AHB{n}PRIVC (n=1..5) — Privileged protection of AHB{n} configuration bits (enable, ready, divider)
  [2] AHBMPRIVC — Privileged protection of AHBM configuration bits (enable, ready, divider)
  [1] ACLKNCPRIVC — Privileged protection of ACLKNC configuration bits (enable, ready, divider)
  [0] ACLKNPRIVC — Privileged protection of ACLKN configuration bits (enable, ready, divider)
0x17CC PUBCFGCR4 — RCC public configuration clear register 4
  [13] NOCPUBC — Public protection of NOC configuration bits (enable, ready, divider)
  [n+7] APB{n}PUBC (n=1..5) — Public protection of APB{n} configuration bits (enable, ready, divider)
  [n+2] AHB{n}PUBC (n=1..5) — Public protection of AHB{n} configuration bits (enable, ready, divider)
  [2] AHBMPUBC — Public protection of AHBM configuration bits (enable, ready, divider)
  [1] ACLKNCPUBC — Public protection of ACLKNC configuration bits (enable, ready, divider)
  [0] ACLKNPUBC — Public protection of ACLKN configuration bits (enable, ready, divider)
0x17D0 PUBCFGCR5 — RCC public configuration clear register 5
  [11] VENCRAMPUBC — Public protection of VENCRAM configuration bits (enable, ready, divider)
  [10] CACHEAXIRAMPUBC — Public protection of CACHEAXIRAM configuration bits
  [9] FLEXRAMPUBC — Public protection of FLEXRAM configuration bits (enable, ready, divider)
  [8] AXISRAM2PUBC — Public protection of AXISRAM2 configuration bits (enable, ready, divider)
  [7] AXISRAM1PUBC — Public protection of AXISRAM1 configuration bits (enable, ready, divider)
  [6] BKPSRAMPUBC — Public protection of BKPSRAM configuration bits (enable, ready, divider)
  [5] AHBSRAM2PUBC — Public protection of AHBSRAM2 configuration bits (enable, ready, divider)
  [4] AHBSRAM1PUBC — Public protection of AHBSRAM1 configuration bits (enable, ready, divider)
  [n-3] AXISRAM{n}PUBC (n=3..6) — Public protection of AXISRAM{n} configuration bits (enable, ready, divider)
